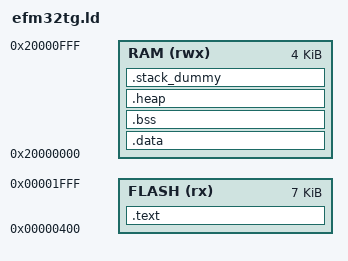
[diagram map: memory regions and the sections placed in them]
/* Linker script for Energy Micro EFM32TG devices */
/*                                                                  */
/* This file is subject to the license terms as defined in ARM's    */
/* CMSIS END USER LICENSE AGREEMENT.pdf, governing the use of       */
/* Example Code.                                                    */
/*                                                                  */
/* Energy Micro AS, 2012                                            */
MEMORY
{
    FLASH (rx) : ORIGIN = 0x00000400, LENGTH = 7168
    RAM (rwx)  : ORIGIN = 0x20000000, LENGTH = 4096
}

/* Linker script to place sections and symbol values. Should be used together
 * with other linker script that defines memory regions FLASH and RAM.
 * It references following symbols, which must be defined in code:
 *   Reset_Handler : Entry of reset handler
 *
 * It defines following symbols, which code can use without definition:
 *   __exidx_start
 *   __exidx_end
 *   __etext
 *   __data_start__
 *   __preinit_array_start
 *   __preinit_array_end
 *   __init_array_start
 *   __init_array_end
 *   __fini_array_start
 *   __fini_array_end
 *   __data_end__
 *   __bss_start__
 *   __bss_end__
 *   __end__
 *   end
 *   __HeapLimit
 *   __StackLimit
 *   __StackTop
 *   __stack
 */
ENTRY(Reset_Handler)

SECTIONS
{
    .text :
    {
        KEEP(*(.isr_vector))
        *(.text.*)
        *(.rodata)
        *(.rodata.*)
        *(.text)
    } > FLASH

    __etext = .;

    .data : AT (__etext)
    {
        __data_start__ = .;
        *(.textrw)
        *(.data*)
        . = ALIGN(4);
        /* All data end */
        __data_end__ = .;

    } > RAM

    .bss :
    {
        __bss_start__ = .;
        *(.bss*)
        *(COMMON)
        __bss_end__ = .;
    } > RAM

    .heap :
    {
        __end__ = .;
        end = __end__;
        _end = __end__;
        *(.heap*)
        __HeapLimit = .;
    } > RAM

    /* .stack_dummy section doesn't contains any symbols. It is only
    * used for linker to calculate size of stack sections, and assign
    * values to stack symbols later */
    .stack_dummy :
    {
        *(.stack)
    } > RAM

    /* Set stack top to end of RAM, and stack limit move down by
     * size of stack_dummy section */

    __StackTop = ORIGIN(RAM) + LENGTH(RAM);
    __StackLimit = __StackTop - SIZEOF(.stack_dummy);
    PROVIDE(__stack = __StackTop);

    /* Check if data + heap + stack exceeds RAM limit */
    ASSERT(__StackLimit >= __HeapLimit, "region RAM overflowed with stack")
}
